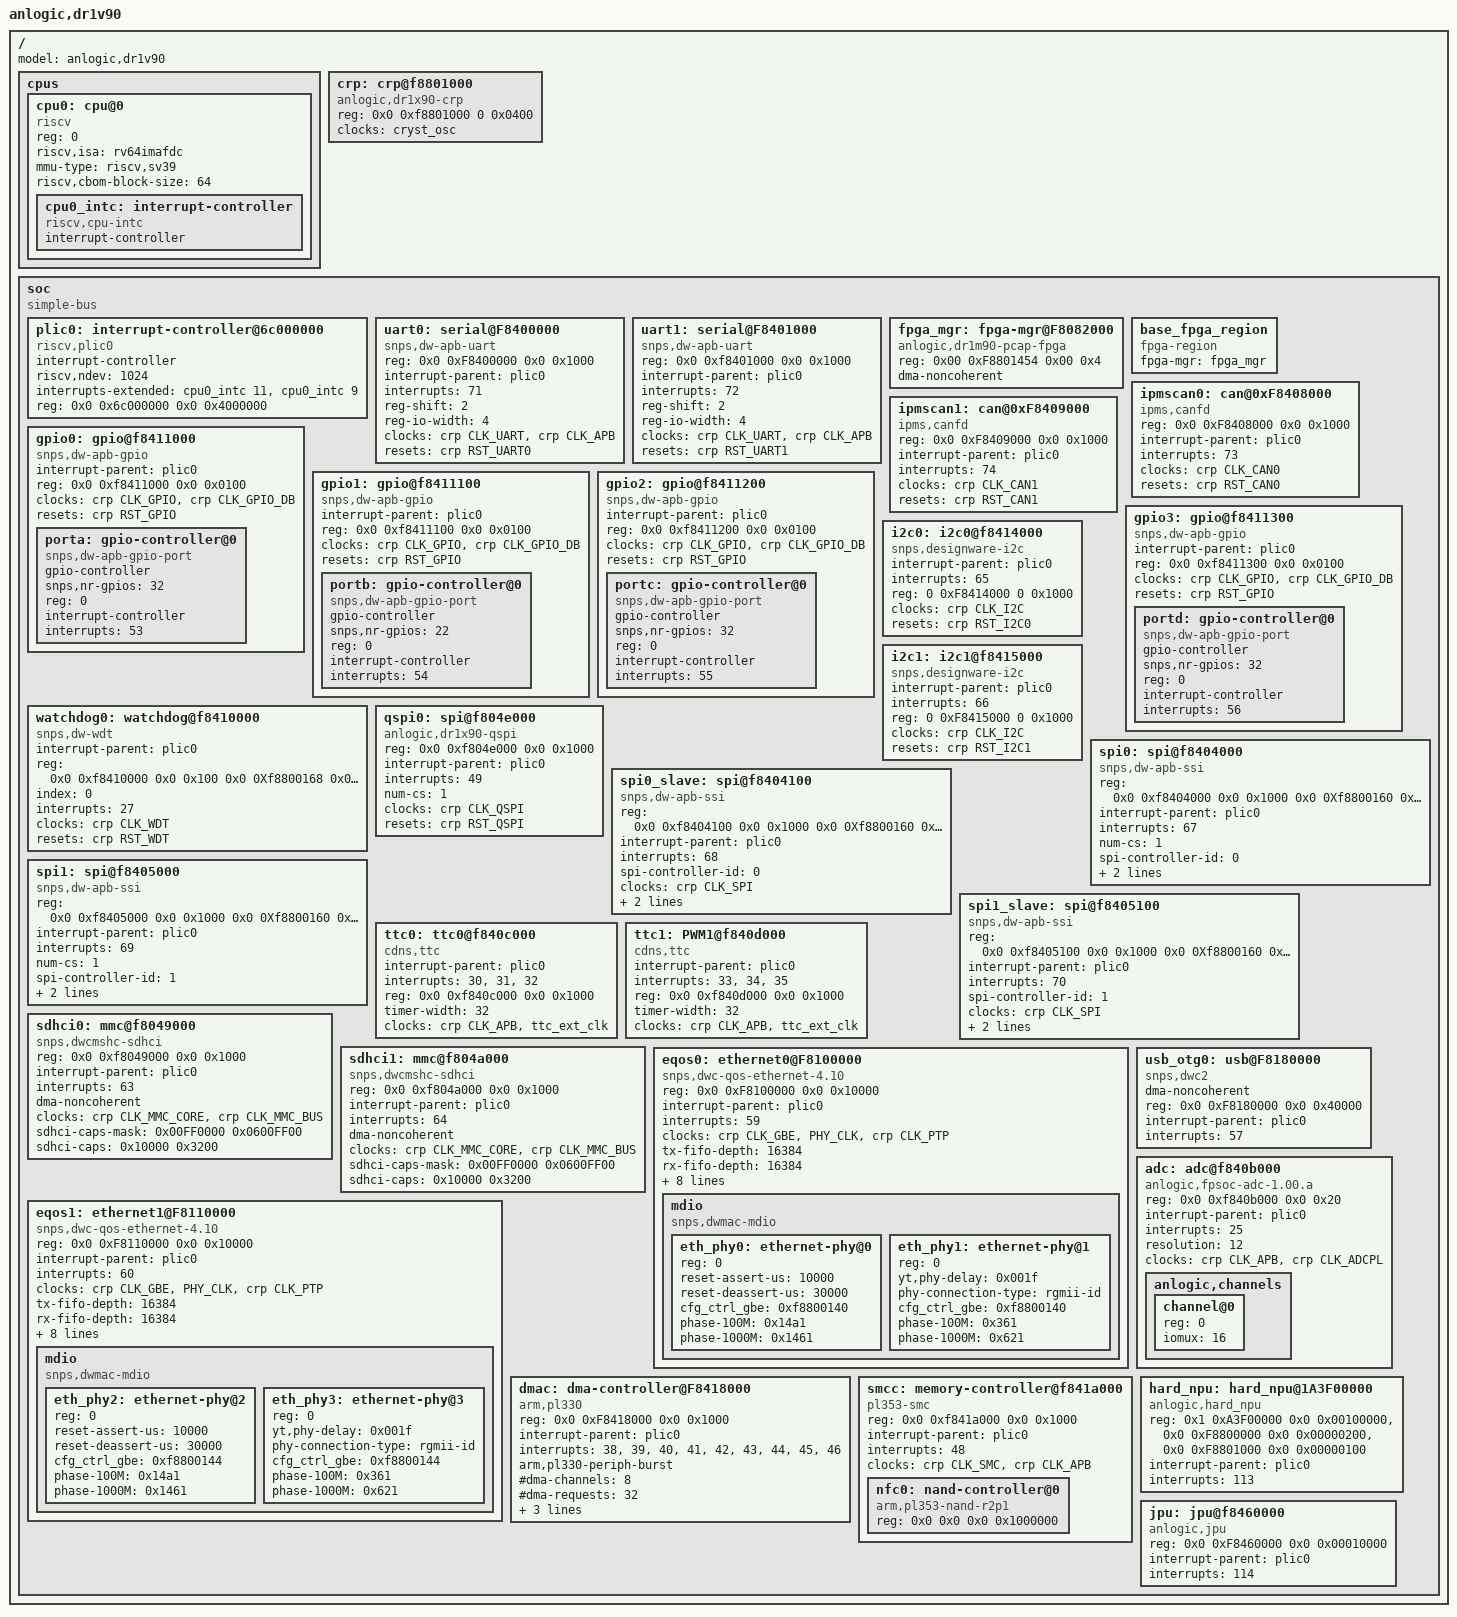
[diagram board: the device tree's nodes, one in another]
// SPDX-License-Identifier: (GPL-2.0+ OR MIT)

#include "anlogic-dr1v90-plat.h"

/dts-v1/;
#include <dt-bindings/clock/anl_dr1x90_crp.h>
#include <dt-bindings/reset/anl_dr1x90_crp.h>

/ {
	#address-cells = <2>;
	#size-cells = <2>;
	model = "anlogic,dr1v90";

	cpus: cpus {
		#address-cells = <1>;
		#size-cells = <0>;
		cpu0: cpu@0 {
			device_type = "cpu";
			reg = <0>;
			compatible = "riscv";
			riscv,isa = "rv64imafdc";
			mmu-type = "riscv,sv39";
			riscv,cbom-block-size = <64>;
			cpu0_intc: interrupt-controller {
				#interrupt-cells = <1>;
				interrupt-controller;
				compatible = "riscv,cpu-intc";
			};
		};
	};

	crp: crp@f8801000 {
		compatible = "anlogic,dr1x90-crp";
		reg = <0x0 0xf8801000 0 0x0400>;
		clocks = <&cryst_osc>;
		clock-names = "cryst_osc";
		#clock-cells = <1>;
		#reset-cells = <1>;
		status = "okay";
	};

	soc: soc {
		#address-cells = <2>;
		#size-cells = <2>;
		compatible = "simple-bus";
		ranges;

		plic0: interrupt-controller@6c000000 {
			#interrupt-cells = <1>;
			compatible = "riscv,plic0";
			interrupt-controller;
			riscv,ndev = <1024>;
			interrupts-extended = <&cpu0_intc 11 &cpu0_intc 9>;
			reg = <0x0 0x6c000000 0x0 0x4000000>;
		};

		uart0: serial@F8400000 {
			compatible = "snps,dw-apb-uart";
			reg = <0x0 0xF8400000 0x0 0x1000>;
			interrupt-parent = <&plic0>;
			interrupts = <71>;
			reg-shift  = <2>;
			reg-io-width = <4>;
			clocks = <&crp CLK_UART>, <&crp CLK_APB>;
			clock-names = "baudclk", "apb_pclk";
			resets = <&crp RST_UART0>;
		};

		uart1: serial@F8401000 {
			compatible = "snps,dw-apb-uart";
			reg = <0x0 0xf8401000 0x0 0x1000>;
			interrupt-parent = <&plic0>;
			interrupts = <72>;
			reg-shift = <2>;
			reg-io-width = <4>;
			clocks = <&crp CLK_UART>, <&crp CLK_APB>;
			clock-names = "baudclk", "apb_pclk";
			resets = <&crp RST_UART1>;
		};

		fpga_mgr: fpga-mgr@F8082000 {
			compatible = "anlogic,dr1m90-pcap-fpga";
			reg = <0x00 0xF8801454 0x00 0x4>;
			dma-noncoherent;
		};

		base_fpga_region {
			#address-cells = <0x2>;
			#size-cells = <0x2>;

			compatible = "fpga-region";
			fpga-mgr = <&fpga_mgr>;
		};

		ipmscan0: can@0xF8408000 {
			compatible = "ipms,canfd";
			reg = <0x0 0xF8408000 0x0 0x1000>;
			interrupt-parent = <&plic0>;
			interrupts = <73>;
			clocks = <&crp CLK_CAN0>;
			clock-names = "ipms_can_clk";
			resets = <&crp RST_CAN0>;
		};

		ipmscan1: can@0xF8409000 {
			compatible = "ipms,canfd";
			reg = <0x0 0xF8409000 0x0 0x1000>;
			interrupt-parent = <&plic0>;
			interrupts = <74>;
			clocks = <&crp CLK_CAN1>;
			clock-names = "ipms_can_clk";
			resets = <&crp RST_CAN1>;
		};

		gpio0: gpio@f8411000 {
			compatible = "snps,dw-apb-gpio";
			interrupt-parent = <&plic0>;
			reg = <0x0 0xf8411000 0x0 0x0100>;
			#address-cells = <1>;
			#size-cells = <0>;
			clocks = <&crp CLK_GPIO>, <&crp CLK_GPIO_DB>;
			clock-names = "bus", "db";
			resets = <&crp RST_GPIO>;

			porta: gpio-controller@0 {
				compatible = "snps,dw-apb-gpio-port";
				gpio-controller;
				#gpio-cells = <2>;
				snps,nr-gpios = <32>;
				reg = <0>;
				interrupt-controller;
				#interrupt-cells = <2>;
				interrupts = <53>;
			};
		};

		gpio1: gpio@f8411100 {
			compatible = "snps,dw-apb-gpio";
			interrupt-parent = <&plic0>;
			reg = <0x0 0xf8411100 0x0 0x0100>;
			#address-cells = <1>;
			#size-cells = <0>;
			clocks = <&crp CLK_GPIO>, <&crp CLK_GPIO_DB>;
			clock-names = "bus", "db";
			resets = <&crp RST_GPIO>;

			portb: gpio-controller@0 {
				compatible = "snps,dw-apb-gpio-port";
				gpio-controller;
				#gpio-cells = <2>;
				snps,nr-gpios = <22>;
				reg = <0>;
				interrupt-controller;
				#interrupt-cells = <2>;
				interrupts = <54>;
			};
		};

		gpio2: gpio@f8411200 {
			compatible = "snps,dw-apb-gpio";
			interrupt-parent = <&plic0>;
			reg = <0x0 0xf8411200 0x0 0x0100>;
			#address-cells = <1>;
			#size-cells = <0>;
			clocks = <&crp CLK_GPIO>, <&crp CLK_GPIO_DB>;
			clock-names = "bus", "db";
			resets = <&crp RST_GPIO>;

			portc: gpio-controller@0 {
				compatible = "snps,dw-apb-gpio-port";
				gpio-controller;
				#gpio-cells = <2>;
				snps,nr-gpios = <32>;
				reg = <0>;
				interrupt-controller;
				#interrupt-cells = <2>;
				interrupts = <55>;
			};
		};

		gpio3: gpio@f8411300 {
			compatible = "snps,dw-apb-gpio";
			interrupt-parent = <&plic0>;
			reg = <0x0 0xf8411300 0x0 0x0100>;
			#address-cells = <1>;
			#size-cells = <0>;
			clocks = <&crp CLK_GPIO>, <&crp CLK_GPIO_DB>;
			clock-names = "bus", "db";
			resets = <&crp RST_GPIO>;

			portd: gpio-controller@0 {
				compatible = "snps,dw-apb-gpio-port";
				gpio-controller;
				#gpio-cells = <2>;
				snps,nr-gpios = <32>;
				reg = <0>;
				interrupt-controller;
				#interrupt-cells = <2>;
				interrupts = <56>;
			};
		};

		i2c0: i2c0@f8414000 {
			compatible = "snps,designware-i2c";
			interrupt-parent = <&plic0>;
			interrupts = <65>;
			reg = <0 0xF8414000 0 0x1000>;
			#address-cells = <1>;
			#size-cells = <0>;
			clocks = <&crp CLK_I2C>;
			clock-names = "IIC_CLK";
			resets = <&crp RST_I2C0>;
		};

		i2c1: i2c1@f8415000 {
			compatible = "snps,designware-i2c";
			interrupt-parent = <&plic0>;
			interrupts = <66>;
			reg = <0 0xF8415000 0 0x1000>;
			#address-cells = <1>;
			#size-cells = <0>;
			clocks = <&crp CLK_I2C>;
			clock-names = "IIC_CLK";
			resets = <&crp RST_I2C1>;
		};

		watchdog0: watchdog@f8410000 {
			compatible = "snps,dw-wdt";
			interrupt-parent = <&plic0>;
			#address-cells = <2>;
			#size-cells = <2>;
			reg = <0x0 0xf8410000 0x0 0x100 0x0 0Xf8800168 0x0 0x20>;
			index = <0>;
			interrupts = <27>;
			clocks = <&crp CLK_WDT>;
			resets = <&crp RST_WDT>;
		};


		qspi0: spi@f804e000 {
			compatible = "anlogic,dr1x90-qspi";
			reg = <0x0 0xf804e000 0x0 0x1000>;
			#address-cells = <1>;
			#size-cells = <0>;
			interrupt-parent = <&plic0>;
			interrupts = <49>;
			num-cs = <1>;
			clocks = <&crp CLK_QSPI>;
			resets = <&crp RST_QSPI>;
			reset-names = "spi";
		};

		spi0: spi@f8404000 {
			compatible = "snps,dw-apb-ssi";
			#address-cells = <1>;
			#size-cells = <0>;
			reg = <0x0 0xf8404000 0x0 0x1000 0x0 0Xf8800160 0x0 0x20>;
			interrupt-parent = <&plic0>;
			interrupts = <67>;
			num-cs = <1>;
			spi-controller-id = <0>;
			clocks = <&crp CLK_SPI>;
			resets = <&crp RST_SPI0>;
			reset-names = "spi";
		};

		spi0_slave: spi@f8404100 {
			compatible = "snps,dw-apb-ssi";
			#address-cells = <2>;
			#size-cells = <2>;
			reg = <0x0 0xf8404100 0x0 0x1000 0x0 0Xf8800160 0x0 0x20>;
			interrupt-parent = <&plic0>;
			interrupts = <68>;
			spi-controller-id = <0>;
			clocks = <&crp CLK_SPI>;
			resets = <&crp RST_SPI0>;
			reset-names = "spi";
			spi-slave;
		};

		spi1: spi@f8405000 {
			compatible = "snps,dw-apb-ssi";
			#address-cells = <1>;
			#size-cells = <0>;
			reg = <0x0 0xf8405000 0x0 0x1000 0x0 0Xf8800160 0x0 0x20>;
			interrupt-parent = <&plic0>;
			interrupts = <69>;
			num-cs = <1>;
			spi-controller-id = <1>;
			clocks = <&crp CLK_SPI>;
			resets = <&crp RST_SPI1>;
			reset-names = "spi";
		};

		spi1_slave: spi@f8405100 {
			compatible = "snps,dw-apb-ssi";
			#address-cells = <2>;
			#size-cells = <2>;
			reg = <0x0 0xf8405100 0x0 0x1000 0x0 0Xf8800160 0x0 0x20>;
			interrupt-parent = <&plic0>;
			interrupts = <70>;
			spi-controller-id = <1>;
			clocks = <&crp CLK_SPI>;
			resets = <&crp RST_SPI1>;
			reset-names = "spi";
			spi-slave;
		};

		ttc0: ttc0@f840c000 {
			compatible = "cdns,ttc";
			interrupt-parent = <&plic0>;
			interrupts = <30>, <31>, <32>;
			reg = <0x0 0xf840c000 0x0 0x1000>;
			timer-width = <32>;
			clocks = <&crp CLK_APB>, <&ttc_ext_clk>;
		};

		ttc1: PWM1@f840d000 {
			compatible = "cdns,ttc";
			#pwm-cells = <3>;
			interrupt-parent = <&plic0>;
			interrupts = <33>, <34>, <35>;
			reg = <0x0 0xf840d000 0x0 0x1000>;
			timer-width = <32>;
			clocks = <&crp CLK_APB>, <&ttc_ext_clk>;
		};

		sdhci0: mmc@f8049000 {
			compatible = "snps,dwcmshc-sdhci";
			reg = <0x0 0xf8049000 0x0 0x1000>;
			interrupt-parent = <&plic0>;
			interrupts = <63>;
			dma-noncoherent;
			clocks = <&crp CLK_MMC_CORE>, <&crp CLK_MMC_BUS>;
			clock-names = "core", "bus";
			sdhci-caps-mask = <0x00FF0000 0x0600FF00>;
			sdhci-caps = <0x10000 0x3200>;
		};

		sdhci1: mmc@f804a000 {
			compatible = "snps,dwcmshc-sdhci";
			reg = <0x0 0xf804a000 0x0 0x1000>;
			interrupt-parent = <&plic0>;
			interrupts = <64>;
			dma-noncoherent;
			clocks = <&crp CLK_MMC_CORE>, <&crp CLK_MMC_BUS>;
			clock-names = "core", "bus";
			sdhci-caps-mask = <0x00FF0000 0x0600FF00>;
			sdhci-caps = <0x10000 0x3200>;
		};

		eqos0: ethernet0@F8100000 {
			compatible = "snps,dwc-qos-ethernet-4.10";
			#address-cells = <2>;
			#size-cells = <2>;
			reg = <0x0 0xF8100000 0x0 0x10000>;
			interrupt-parent = <&plic0>;
			interrupts = <59>;
			clocks = <&crp CLK_GBE>,<&PHY_CLK>,<&crp CLK_PTP>;
			clock-names = "apb_pclk","phy_ref_clk","ptp_ref";
			/* mac-address = [e0 78 a3 01 02 01]; */
			tx-fifo-depth = <16384>;
			rx-fifo-depth = <16384>;
			dma-noncoherent;
			#snps,fixed-burst;
			snps,mixed-burst;
			snps,pbl = <2>;
			snps,en-tx-lpi-clockgating;
			snps,tso;
			phy-mode = "rgmii";
			phy-addr = <0x001>;

			mdio {
				compatible = "snps,dwmac-mdio";
				#address-cells = <1>;
				#size-cells = <0>;

				eth_phy0: ethernet-phy@0 {
					/* Realtek RTL8211F (0x001cc916) */
					reg = <0>;
					reset-assert-us = <10000>;
					reset-deassert-us = <30000>;
					cfg_ctrl_gbe = <0xf8800140>;
					phase-100M = <0x14a1>;
					phase-1000M = <0x1461>;
				};

				eth_phy1: ethernet-phy@1 {
					/* Motorcomm YT8531 (0x4f51e91b) */
					reg = <0>;
					yt,phy-delay = <0x001f>;
					phy-connection-type = "rgmii-id";
					cfg_ctrl_gbe = <0xf8800140>;
					phase-100M = <0x361>;
					phase-1000M = <0x621>;
				};
			};
		};

		eqos1: ethernet1@F8110000 {
			compatible = "snps,dwc-qos-ethernet-4.10";
			#address-cells = <2>;
			#size-cells = <2>;
			reg = <0x0 0xF8110000 0x0 0x10000>;
			interrupt-parent = <&plic0>;
			interrupts = <60>;
			clocks = <&crp CLK_GBE>,<&PHY_CLK>,<&crp CLK_PTP>;
			clock-names = "apb_pclk","phy_ref_clk","ptp_ref";
			/* mac-address = [e0 78 a3 01 02 03]; */
			tx-fifo-depth = <16384>;
			rx-fifo-depth = <16384>;
			dma-noncoherent;
			#snps,fixed-burst;
			snps,mixed-burst;
			snps,pbl = <2>;
			snps,en-tx-lpi-clockgating;
			snps,tso;
			phy-mode = "rgmii";
			phy-addr = <0x011>;

			mdio {
				compatible = "snps,dwmac-mdio";
				#address-cells = <1>;
				#size-cells = <0>;

				eth_phy2: ethernet-phy@2 {
					/* Realtek RTL8211F (0x001cc916) */
					reg = <0>;
					reset-assert-us = <10000>;
					reset-deassert-us = <30000>;
					cfg_ctrl_gbe = <0xf8800144>;
					phase-100M = <0x14a1>;
					phase-1000M = <0x1461>;
				};

				eth_phy3: ethernet-phy@3 {
					/* Motorcomm YT8531 (0x4f51e91b) */
					reg = <0>;
					yt,phy-delay = <0x001f>;
					phy-connection-type = "rgmii-id";
					cfg_ctrl_gbe = <0xf8800144>;
					phase-100M = <0x361>;
					phase-1000M = <0x621>;
				};
			};
		};

		usb_otg0: usb@F8180000 {
			dma-noncoherent;
			compatible = "snps,dwc2";
			#address-cells = <2>;
			#size-cells = <2>;
			reg = <0x0 0xF8180000 0x0 0x40000>;
			interrupt-parent = <&plic0>;
			interrupts = <57>;
		};

		adc:adc@f840b000 {
			compatible = "anlogic,fpsoc-adc-1.00.a";
			#address-cells = <2>;
			#size-cells = <2>;
			reg = <0x0 0xf840b000 0x0 0x20>;
			interrupt-parent = <&plic0>;
			interrupts = <25>;
			resolution = <12>;
			clocks = <&crp CLK_APB>, <&crp CLK_ADCPL>;
			anlogic,channels {
				#address-cells = <1>;
				#size-cells = <0>;
				channel@0 {
					reg = <0>;
					iomux = <16>;
				};
			};
		};

		/*adc continuous acquisition through the GP port*/
		/*
		 * adc:adc@f840b000 {
		 *	 compatible = "anlogic,axi-adc-1.00.a";
		 *	 #address-cells = <2>;
		 *	 #size-cells = <2>;
		 *	 reg = <0x0 0xf840b000 0x0 0x20 0x0 0x80004000 0x0 0x1000>;
		 *	 interrupt-parent = <&plic0>;
		 *	 interrupts = <25>;
		 *	 resolution = <12>;
		 *	 anlogic,channels {
		 *		 #address-cells = <1>;
		 *		 #size-cells = <0>;
		 *		 channel@0 {
		 *			 reg = <0>;
		 *			 iomux = <16>;
		 *		 };
		 *	 };
		 * };
		 */


		dmac: dma-controller@F8418000 {
			compatible = "arm,pl330", "arm,primecell";
			reg = <0x0 0xF8418000  0x0 0x1000>;
			interrupt-parent = <&plic0>;
			interrupts = <38>,
						<39>,
						<40>,
						<41>,
						<42>,
						<43>,
						<44>,
						<45>,
						<46>;
			arm,pl330-periph-burst;
			#dma-cells = <1>;
			#dma-channels = <8>;
			#dma-requests = <32>;
			dma-noncoherent;
			clock-names = "apb_pclk";
			clocks = <&crp CLK_APB>;
			resets = <&crp RST_DMAC_AXI>;
			reset-names = "dma-ocp";
		};

		smcc: memory-controller@f841a000 {
			compatible = "pl353-smc", "arm,primecell";
			#address-cells = <2>;
			#size-cells = <2>;
			reg = <0x0 0xf841a000 0x0 0x1000>;
			interrupt-parent = <&plic0>;
			interrupts = <48>;
			clock-names = "memclk", "apb_pclk";
			clocks = <&crp CLK_SMC>, <&crp CLK_APB>;
			ranges = <0x0 0x0 0x1 0xA4000000 0x0 0x1000000>; /* Nand CS region */

			nfc0: nand-controller@0 {
				compatible = "arm,pl353-nand-r2p1";
				reg = <0x0 0x0 0x0 0x1000000>;
				#address-cells = <1>;
				#size-cells = <0>;
			};
		};

		hard_npu: hard_npu@1A3F00000 {
			compatible = "anlogic,hard_npu";
			reg = <0x1 0xA3F00000 0x0 0x00100000>,
				<0x0 0xF8800000 0x0 0x00000200>,
				<0x0 0xF8801000 0x0 0x00000100>;
			interrupt-parent = <&plic0>;
			interrupts = <113>;
		};

		jpu: jpu@f8460000 {
			compatible = "anlogic,jpu";
			reg = <0x0 0xF8460000 0x0 0x00010000>;
			interrupt-parent = <&plic0>;
			interrupts = <114>;
		};
	};
};
